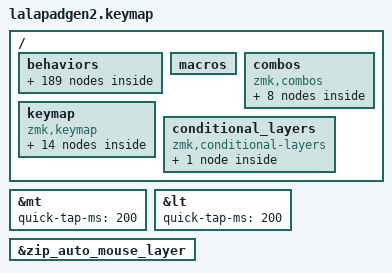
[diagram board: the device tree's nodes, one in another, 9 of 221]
#include <input/processors.dtsi>
#include <dt-bindings/zmk/zip_dynamic_scale.h>
#include <behaviors.dtsi>
#include <dt-bindings/zmk/bt.h>
#include <dt-bindings/zmk/keys.h>
#include <dt-bindings/zmk/outputs.h>
#include <dt-bindings/zmk/pointing.h>
#include <behaviors/kana.dtsi>
#include <dt-bindings/kana/kanji.h>
#include <behaviors/mouse_button_toggle.dtsi>
#include <dt-bindings/lalapad/cursor_slow.h>
#include <dt-bindings/lalapad/tp_keys.h>
#include <dt-bindings/lalapad/tp_positions.h>

#define DEFAULT_LAYER   0
#define CONTROL_LAYER   13
#define SECONDARY_LAYER 1
#define TERTIARY_LAYER  2
#define SYSTEM_LAYER    3
#define MOUSE_LAYER     4
#define KANA_LAYER      5
#define KANA_L_LAYER    6
#define KANA_R_LAYER    7
#define KANA_SYM_LAYER  8
#define LEFT_HAND_LAYER  9
#define LEFT_HAND2_LAYER 10
#define LEFT_HAND3_LAYER 11
#define LEFT_HAND4_LAYER 12

// &mt・&lt: 短く押してから 200ms 以内にもう一度押し続けると、長押しにせずタップを押し続ける（Space の連続入力など）。
// &mt は今どこにも置いていない（エディタで置いたときの既定）
&mt { quick-tap-ms = <200>; };

&lt { quick-tap-ms = <200>; };

// オートマウスレイヤー（lalapadgen2.dtsi）のうち、マウスレイヤーに結びつく設定
// - layer: トラックパッドを操作したときに有効にするレイヤー。timeout-ms: 指とキーを離してから解除するまでの時間
// - excluded-layers: 数字・記号レイヤーの間は、トラックパッドを操作してもマウスレイヤーにしない
// - excluded-positions: マウスレイヤーで &trans でも、押しても解除せず、押している間は時間切れにしない位置
//   （トラックパッドのクリック・ジェスチャー 52〜67。POS_TP_* は dt-bindings/lalapad/tp_positions.h。離してから数え直す）
// - passive-positions: マウスレイヤーに割り当てがあっても、押しても解除も延長もしない位置（親指の段の 30〜41 のうち、
//   33・34 以外。マウスレイヤーで &trans の位置（36〜38）は、ほかのキーと同じく押すと解除する）
&zip_auto_mouse_layer {
    layer = <MOUSE_LAYER>;
    timeout-ms = <350>;
    excluded-layers = <SECONDARY_LAYER TERTIARY_LAYER>;
    excluded-positions = <
        POS_TP_LCLK_L POS_TP_RCLK_L POS_TP_MCLK_L POS_TP_LCLK_R POS_TP_RCLK_R POS_TP_MCLK_R
        POS_TP_SWIPE_RIGHT_L POS_TP_SWIPE_LEFT_L POS_TP_SWIPE_UP_L POS_TP_SWIPE_DOWN_L POS_TP_PINCH_L
        POS_TP_SWIPE_RIGHT_R POS_TP_SWIPE_LEFT_R POS_TP_SWIPE_UP_R POS_TP_SWIPE_DOWN_R POS_TP_PINCH_R
    >;
    passive-positions = <30 31 32 35 36 37 38 39 40 41>;
};


/ {
    behaviors {
        zip_dyn_scale: zip_dyn_scale {
            compatible = "zmk,behavior-zip-dynamic-scale";
            #binding-cells = <2>;
        };

        zip_dyn_scale_set: zip_dyn_scale_set {
            compatible = "zmk,behavior-zip-dynamic-scale-set";
            #binding-cells = <2>;
        };

        // Num Word（自作モジュール lalapad/ の zmk,behavior-word-layer）: 数字レイヤーを、数字と continue-list のキー
        // （Backspace・Delete・. , + - * / =）を押している間だけ続け、ほかのキーを押すと自動で戻す。Shift などの修飾キーでは
        // 戻さない（ignore-modifiers）。ほかの操作（20＋21 のコンボの &to など）で数字レイヤーが解除されたら、こちらも終わる。
        // 記号レイヤー（38）を押したら終える（exit-layers）: 数字レイヤーと記号レイヤーが同時に有効になると
        // システムレイヤー（bootloader・BT_CLR など）になるため。Num Word の間に 38 を押すと、記号レイヤーになる。
        // 使い方: &num_word SECONDARY_LAYER
        num_word: num_word {
            compatible = "zmk,behavior-word-layer";
            #binding-cells = <1>;
            continue-list = <BACKSPACE DELETE DOT COMMA PLUS MINUS STAR FSLH EQUAL>;
            ignore-numbers;
            ignore-modifiers;
            exit-layers = <TERTIARY_LAYER>;
        };

        // 33 の長押し: 押している間だけ数字レイヤー（&mo と同じ）。Num Word の間に押したら、Num Word を引き継ぐ
        // （ほかのキーや 38 を押しても数字レイヤーのまま。33 と 38 でシステムレイヤーになる）。
        // 使い方: &num_hold SECONDARY_LAYER
        num_hold: num_hold {
            compatible = "zmk,behavior-word-layer";
            #binding-cells = <1>;
            momentary;
        };

        // 33: タップで Num Word（数字レイヤーを、数字を打っている間だけ続ける）、長押しで今までどおり押している間だけ
        // 数字レイヤー（num_hold）。長押しの間にほかのキーを押したら、すぐに長押しとして扱う（hold-preferred）。
        // 使い方: &num_mo SECONDARY_LAYER SECONDARY_LAYER
        num_mo: num_mo {
            compatible = "zmk,behavior-hold-tap";
            #binding-cells = <2>;
            flavor = "hold-preferred";
            tapping-term-ms = <200>;
            bindings = <&num_hold>, <&num_word>;
        };

        mt2: mod_tap2 {
            compatible = "zmk,behavior-hold-tap";
            #binding-cells = <2>;
            flavor = "tap-preferred";
            tapping-term-ms = <350>;
            quick-tap-ms = <200>;
            // require-prior-idle-ms（以前は 125）は外した。直前の打鍵から 125ms 以内に押すと、長押ししても
            // Shift にならず、押したままのタップとして rrrr と連続入力になったため。戻すときは次の行を足す
            //   require-prior-idle-ms = <125>;
            bindings = <&kp>, <&kp>;
        };

        // ===== カスタムキー（エディタで使いたいレイヤーに割り当てる） =====
        // 名前の頭で種類を分けている（clk_: クリック、cur_: カーソル、mod_: 修飾キー、swap_: ウィンドウの切り替え、scr_: スクロール、lyr_: レイヤー、num_: Num Word、link_: Chrome のリンク、tp_: トラックパッドでキー操作、ks_: かなと一緒に打つ記号、pair_: カッコ、sym_: 記号、kj_: 漢字 1 文字、kana_: かな）。
        // display-name は ZMK Studio の一覧とキーの上に出る名前（キーの上は 9 文字まで）。

        // --- clk_: クリック押しっぱなし（もう一度押す、または同じボタンのクリックで解除） ---
        // 左クリック押しっぱなし（旧 D.LCK）
        clk_lock_l: clk_lock_l {
            compatible = "zmk,behavior-mouse-button-toggle";
            display-name = "L Lock";
            #binding-cells = <0>;
            button = <LCLK>;
        };
        // 中クリック押しっぱなし（旧 D.MID）
        clk_lock_m: clk_lock_m {
            compatible = "zmk,behavior-mouse-button-toggle";
            display-name = "M Lock";
            #binding-cells = <0>;
            button = <MCLK>;
        };
        // 右クリック押しっぱなし（旧 D.RCK）
        clk_lock_r: clk_lock_r {
            compatible = "zmk,behavior-mouse-button-toggle";
            display-name = "R Lock";
            #binding-cells = <0>;
            button = <RCLK>;
        };

        // --- cur_: カーソル低速（1/3） ---
        // 押している間、カーソル低速（旧 SLOW）
        cur_slow_hold: cur_slow_hold {
            compatible = "zmk,behavior-cursor-slow";
            display-name = "Slow Hold";
            #binding-cells = <0>;
            mode = <CURSOR_SLOW_HOLD>;
        };
        // 押すたびにカーソル低速のオン・オフ（旧 T.SLO）
        cur_slow_toggle: cur_slow_toggle {
            compatible = "zmk,behavior-cursor-slow";
            display-name = "Slow Tog";
            #binding-cells = <0>;
            mode = <CURSOR_SLOW_TOGGLE>;
        };
        // 次のキーを押すまでカーソル低速（旧 O.SLO）
        cur_slow_once: cur_slow_once {
            compatible = "zmk,behavior-cursor-slow";
            display-name = "Slow Once";
            #binding-cells = <0>;
            mode = <CURSOR_SLOW_ONESHOT>;
        };

        // --- mod_: 修飾キー押しっぱなし（もう一度押すと解除） ---
        // Left Alt 押しっぱなし（旧 A.LCK）
        mod_lock_alt: mod_lock_alt {
            compatible = "zmk,behavior-key-lock";
            display-name = "Alt Lock";
            #binding-cells = <0>;
            keycode = <LALT>;
        };
        // Left Ctrl 押しっぱなし（旧 C.LCK）
        mod_lock_ctrl: mod_lock_ctrl {
            compatible = "zmk,behavior-key-lock";
            display-name = "Ctrl Lock";
            #binding-cells = <0>;
            keycode = <LCTRL>;
        };
        // Left Shift 押しっぱなし（旧 S.LCK）
        mod_lock_shift: mod_lock_shift {
            compatible = "zmk,behavior-key-lock";
            display-name = "Shft Lock";
            #binding-cells = <0>;
            keycode = <LSHIFT>;
        };
        // Left GUI（Win）押しっぱなし（旧 W.LCK）
        mod_lock_win: mod_lock_win {
            compatible = "zmk,behavior-key-lock";
            display-name = "Win Lock";
            #binding-cells = <0>;
            keycode = <LGUI>;
        };

        // --- swap_: ウィンドウの切り替え（Alt+Tab。自作モジュール lalapad/ の zmk,behavior-alt-tab） ---
        // 最初に押したときに Alt を押したままにして、押すたびに Tab（swap_prev は Shift+Tab）を送る。
        // 押し始めたときのレイヤーを離す（&mo のキーを離す）か、ほかのキー（キーコードを送るもの。クリックやレイヤーのキーは除く）を押すと
        // Alt を離して、選んだウィンドウに切り替わる。
        // swap_next と swap_prev は Alt を共有するので、どちらから押し始めても、途中で入れ替えてもよい
        swap_next: swap_next {
            compatible = "zmk,behavior-alt-tab";
            display-name = "Alt Tab";
            #binding-cells = <0>;
        };
        swap_prev: swap_prev {
            compatible = "zmk,behavior-alt-tab";
            display-name = "AltShTab";
            #binding-cells = <0>;
            reverse;
        };

        // --- scr_: スクロール ---
        // 押している間だけ、トラックパッドの2本指スクロールを縦か横のどちらかにそろえる（スクロールスナップ）。
        // レイヤーは使わない。実際の処理は lalapadgen2.dtsi の &zip_scroll_snap_gate_R / _L
        scr_snap_hold: scr_snap_hold {
            compatible = "zmk,behavior-scroll-snap-hold";
            display-name = "Snap Hold";
            #binding-cells = <0>;
        };

        // --- lyr_: レイヤー ---
        // レイヤーを固定する（Layer Lock。自作モジュール lalapad/ の zmk,behavior-layer-lock）。押すと、このキーを置いたレイヤーを
        // 固定する（&mo のキーを離しても、オートマウスレイヤーの時間切れでも切れない。マウスレイヤーでは、&trans のキーを
        // 押しても切れず、そのキーは下のレイヤーのキーとして入力される）。もう一度押すと固定をやめて、そのレイヤーを解除する
        // （オートマウスレイヤーなら、ふだんどおり手を離してから時間を数え直す）。Default と system_layer（数字＋記号で
        // 有効になるレイヤー）以外のどのレイヤーにも置ける。かなのレイヤーの固定は、かなモードを抜けるとやめる
        lyr_lock: lyr_lock {
            compatible = "zmk,behavior-layer-lock";
            display-name = "Lyr Lock";
            #binding-cells = <0>;
        };

        // --- link_: Chrome のリンク ---
        // カーソルを合わせたリンクを、シークレットウィンドウで開く。右クリックでメニューを出し、
        // メニューの「シークレット ウィンドウでリンクを開く」のアクセスキー G を押す（メニューが出るのを 200ms 待つ）
        link_incognito: link_incognito {
            compatible = "zmk,behavior-macro";
            #binding-cells = <0>;
            wait-ms = <0>;
            tap-ms = <30>;
            bindings
                = <&macro_wait_time 200>
                , <&mkp RCLK>
                , <&macro_wait_time 0>
                , <&kp G>
                ;
            display-name = "Incognito";
        };

        // --- tp_: トラックパッドをキー操作に変える（自作モジュール lalapad/ の zmk,behavior-tp-keys・zmk,behavior-tp-stroke） ---
        // 押している間だけ、トラックパッドの動きを、カーソル・スクロールの代わりにキーの入力に変える
        // （押している間のタップ・ジェスチャーは捨てる）。実際の処理は lalapadgen2.dtsi のリスナーに入れた &zip_tp_keys。
        // 直下の bindings はどのレイヤーでも使う既定。レイヤーごとに変えるときは、子ノード（表）に layers（使うレイヤー）と
        // bindings を書き足す（このキーを押したときに有効なレイヤーを上から見て、表のあるレイヤーの表を使う。表の &trans は
        // 下のレイヤーの表、最後に既定を見る）。左右のトラックパッドで変えるときは left-bindings・right-bindings に書く。
        // 例: num { layers = <SECONDARY_LAYER>; bindings = <...>; };
        // tp-keys の bindings は 8 つ: 1 本指を上・下・左・右へ動かしたとき、2 本指を上・下・左・右へ動かしたとき
        // （2 本指も指を動かした向き。スクロールの向きではない）。4 つとも &trans にした側は、変えずにカーソル（スクロール）のまま。
        // 動き始めの向きで縦か横かを決め、指が触れ直す・離れるか、このキーを押す・離すまで変えない。
        // *-step は 1 回送るのに必要な動きの量（トラックパッドの生の値。速度の設定には影響されない）。
        // 矢印: 1 本指で ←→↑↓、2 本指で上下が PgUp・PgDn、左右が Home・End
        tp_arrow: tp_arrow {
            compatible = "zmk,behavior-tp-keys";
            #binding-cells = <0>;
            bindings
                = <&kp UP>, <&kp DOWN>, <&kp LEFT>, <&kp RIGHT>
                , <&kp PAGE_UP>, <&kp PAGE_DOWN>, <&kp HOME>, <&kp END>
                ;
            cursor-step = <150>;
            scroll-step = <300>;
            display-name = "TP Arrow";
        };
        // ダイヤル: 1 本指で上下が音量、左右がタブ（Ctrl+Shift+Tab・Ctrl+Tab）。
        // 2 本指で上下がウィンドウの切り替え（指を上へ swap_prev・下へ swap_next。このキーを押したレイヤーが切れるか
        // （マウスレイヤーなら、キーとトラックパッドから手を離して 350ms 後）、ほかのキーを押すと、選んだウィンドウに
        // 切り替わる）、左右が仮想デスクトップ（Ctrl+Win+←・→）
        tp_dial: tp_dial {
            compatible = "zmk,behavior-tp-keys";
            #binding-cells = <0>;
            bindings
                = <&kp C_VOL_UP>, <&kp C_VOL_DN>, <&kp LC(LS(TAB))>, <&kp LC(TAB)>
                , <&swap_prev>, <&swap_next>, <&kp LC(LG(LEFT))>, <&kp LC(LG(RIGHT))>
                ;
            cursor-step = <300>;
            scroll-step = <300>;
            display-name = "TP Dial";
        };
        // 一筆書き: 押したまま 1 本指で線を描き、指（またはこのキー）を離すと、描いた向きの並びに合うものを送る。
        // strokes（向きの並び）は全レイヤー共通。bindings は strokes と同じ数・同じ順番（レイヤーごと・左右ごとの書き方は上の tp-keys と同じ）。
        // ← 戻る、→ 進む、↑ 新しいタブ、↓ 再読み込み、↓→ タブを閉じる、↓← 閉じたタブを開き直す、
        // ↑← 前のタブ、↑→ 次のタブ、→↓ シークレットウィンドウ
        tp_draw: tp_draw {
            compatible = "zmk,behavior-tp-stroke";
            #binding-cells = <0>;
            strokes = <
                TP_STROKE1(TP_LEFT)
                TP_STROKE1(TP_RIGHT)
                TP_STROKE1(TP_UP)
                TP_STROKE1(TP_DOWN)
                TP_STROKE2(TP_DOWN, TP_RIGHT)
                TP_STROKE2(TP_DOWN, TP_LEFT)
                TP_STROKE2(TP_UP, TP_LEFT)
                TP_STROKE2(TP_UP, TP_RIGHT)
                TP_STROKE2(TP_RIGHT, TP_DOWN)
                >;
            bindings
                = <&kp LA(LEFT)>
                , <&kp LA(RIGHT)>
                , <&kp LC(T)>
                , <&kp F5>
                , <&kp LC(W)>
                , <&kp LC(LS(T))>
                , <&kp LC(LS(TAB))>
                , <&kp LC(TAB)>
                , <&kp LC(LS(N))>
                ;
            stroke-step = <300>;
            display-name = "TP Draw";
        };

        // --- sym_: 記号（Windows の Alt コードで送るもの。IME の状態やローマ字テーブルに関係なく入る） ---
        // ふだんは下のほうにあるローマ字テーブル版（sym_hbar_ime など）を使う。こちらは、ローマ字テーブルに
        // 登録していない PC で使うための予備（どのレイヤーにも置いていない）。
        // commit-ime: 先に IME オフで確定前の文字を確定させ、送り終えたら IME オンに戻す
        // （付けないと、確定前の文字があるときに、続きが記号の前に入ってしまう）
        // ―― （ホリゾンタルバー2つ。ダッシュ）を入力。日本語 Windows（cp932）の Alt+33116（Shift_JIS 0x815C）を2回送る。
        // Num Lock がオフなら一時的にオンにして、送り終えたら元に戻す（CONFIG_ZMK_HID_INDICATORS）
        sym_hbar: sym_hbar {
            compatible = "zmk,behavior-alt-code";
            display-name = "―― Alt";
            #binding-cells = <0>;
            codes = <33116 33116>;
            commit-ime;
            // 送る操作（押す・離す）が多い（最大 32）ので、pair_cquote と同じく間隔を広げる
            tap-ms = <10>;
            wait-ms = <10>;
        };
        // ～ （全角チルダ U+FF5E）を入力。日本語 Windows（cp932）の Alt+33120（Shift_JIS 0x8160）で送る。
        sym_tilde: sym_tilde {
            compatible = "zmk,behavior-alt-code";
            display-name = "～ Alt";
            #binding-cells = <0>;
            codes = <33120>;
            commit-ime;
        };
        // “” を入力してカーソルを中に。Alt+33127 = “、Alt+33128 = ”（Shift_JIS 0x8167・0x8168）
        pair_cquote: pair_cquote {
            compatible = "zmk,behavior-alt-code";
            display-name = "“” Alt";
            #binding-cells = <0>;
            codes = <33127 33128>;
            cursor-left = <1>;
            commit-ime;
            // 送る操作（押す・離す）が多い（最大 34）ので、Bluetooth の送信待ちがあふれないよう間隔を広げる
            tap-ms = <10>;
            wait-ms = <10>;
        };

        // --- kj_: 漢字 1 文字（ミニ漢直。Windows の Alt コードで送る。ローマ字テーブルに関係なく、確定した文字で入る） ---
        // 押すと Num Word を終える（「3時」のように打ったら、元のレイヤーに戻る）。数字レイヤーの 20〜22 に置いている
        // （20＋21 は左手用レイヤーに入る同時押しでもあるので、日・人 は同時押しの判定の分だけ遅れて入り、ほぼ同時に押すと入らない）。
        // commit-ime: IME オンで打った確定前の数字（「3」）を先に確定させる（付けないと「時3」の順に入る）。
        // 送り終えると IME オンになる（IME オフのときに押した場合も）
        // 時（Shift_JIS 0x8E9E）
        kj_ji: kj_ji {
            compatible = "zmk,behavior-alt-code";
            display-name = "時";
            #binding-cells = <0>;
            codes = <36510>;
            commit-ime;
        };
        // 人（Shift_JIS 0x906C）
        kj_hito: kj_hito {
            compatible = "zmk,behavior-alt-code";
            display-name = "人";
            #binding-cells = <0>;
            codes = <36972>;
            commit-ime;
        };
        // 日（Shift_JIS 0x93FA）
        kj_hi: kj_hi {
            compatible = "zmk,behavior-alt-code";
            display-name = "日";
            #binding-cells = <0>;
            codes = <37882>;
            commit-ime;
        };

        // --- kj_: 漢字 1 文字の続き（漢字の表 docs/google-ime/kanji.tsv の残りの字。Alt コード版。まだどのレイヤーにも置いていない） ---
        // 上の 時・人・日 と同じ作り（commit-ime つき）。名前は、漢字の表の名前（KJ_AU など）を小文字にしたもの。
        // 字 だけは、表の名前（KJ_JI）を小文字にすると上の kj_ji（時）と重なるので、kj_ji2 にしている。
        // 日本語 Windows だけで使える（Shift_JIS の文字コードの 10 進数を、Alt を押したままテンキーで打つ）。
        // 会（Shift_JIS 0x89EF）
        kj_au: kj_au {
            compatible = "zmk,behavior-alt-code";
            display-name = "会";
            #binding-cells = <0>;
            codes = <35311>;
            commit-ime;
        };
        // 部（Shift_JIS 0x9594）
        kj_bu: kj_bu {
            compatible = "zmk,behavior-alt-code";
            display-name = "部";
            #binding-cells = <0>;
            codes = <38292>;
            commit-ime;
        };
        // 分（Shift_JIS 0x95AA）
        kj_bun: kj_bun {
            compatible = "zmk,behavior-alt-code";
            display-name = "分";
            #binding-cells = <0>;
            codes = <38314>;
            commit-ime;
        };
        // 出（Shift_JIS 0x8F6F）
        kj_deru: kj_deru {
            compatible = "zmk,behavior-alt-code";
            display-name = "出";
            #binding-cells = <0>;
            codes = <36719>;
            commit-ime;
        };
        // 入（Shift_JIS 0x93FC）
        kj_hairu: kj_hairu {
            compatible = "zmk,behavior-alt-code";
            display-name = "入";
            #binding-cells = <0>;
            codes = <37884>;
            commit-ime;
        };
        // 話（Shift_JIS 0x9862）
        kj_hanasu: kj_hanasu {
            compatible = "zmk,behavior-alt-code";
            display-name = "話";
            #binding-cells = <0>;
            codes = <39010>;
            commit-ime;
        };
        // 方（Shift_JIS 0x95FB）
        kj_hou: kj_hou {
            compatible = "zmk,behavior-alt-code";
            display-name = "方";
            #binding-cells = <0>;
            codes = <38395>;
            commit-ime;
        };
        // 意（Shift_JIS 0x88D3）
        kj_i: kj_i {
            compatible = "zmk,behavior-alt-code";
            display-name = "意";
            #binding-cells = <0>;
            codes = <35027>;
            commit-ime;
        };
        // 言（Shift_JIS 0x8CBE）
        kj_iu: kj_iu {
            compatible = "zmk,behavior-alt-code";
            display-name = "言";
            #binding-cells = <0>;
            codes = <36030>;
            commit-ime;
        };
        // 字（Shift_JIS 0x8E9A）
        kj_ji2: kj_ji2 {
            compatible = "zmk,behavior-alt-code";
            display-name = "字";
            #binding-cells = <0>;
            codes = <36506>;
            commit-ime;
        };
        // 書（Shift_JIS 0x8F91）
        kj_kaku: kj_kaku {
            compatible = "zmk,behavior-alt-code";
            display-name = "書";
            #binding-cells = <0>;
            codes = <36753>;
            commit-ime;
        };
        // 漢（Shift_JIS 0x8ABF）
        kj_kan: kj_kan {
            compatible = "zmk,behavior-alt-code";
            display-name = "漢";
            #binding-cells = <0>;
            codes = <35519>;
            commit-ime;
        };
        // 考（Shift_JIS 0x8D6C）
        kj_kangaeru: kj_kangaeru {
            compatible = "zmk,behavior-alt-code";
            display-name = "考";
            #binding-cells = <0>;
            codes = <36204>;
            commit-ime;
        };
        // 感（Shift_JIS 0x8AB4）
        kj_kanjiru: kj_kanjiru {
            compatible = "zmk,behavior-alt-code";
            display-name = "感";
            #binding-cells = <0>;
            codes = <35508>;
            commit-ime;
        };
        // 風（Shift_JIS 0x9597）
        kj_kaze: kj_kaze {
            compatible = "zmk,behavior-alt-code";
            display-name = "風";
            #binding-cells = <0>;
            codes = <38295>;
            commit-ime;
        };
        // 気（Shift_JIS 0x8B43）
        kj_ki: kj_ki {
            compatible = "zmk,behavior-alt-code";
            display-name = "気";
            #binding-cells = <0>;
            codes = <35651>;
            commit-ime;
        };
        // 来（Shift_JIS 0x9788）
        kj_kuru: kj_kuru {
            compatible = "zmk,behavior-alt-code";
            display-name = "来";
            #binding-cells = <0>;
            codes = <38792>;
            commit-ime;
        };
        // 見（Shift_JIS 0x8CA9）
        kj_miru: kj_miru {
            compatible = "zmk,behavior-alt-code";
            display-name = "見";
            #binding-cells = <0>;
            codes = <36009>;
            commit-ime;
        };
        // 自（Shift_JIS 0x8EA9）
        kj_mizukara: kj_mizukara {
            compatible = "zmk,behavior-alt-code";
            display-name = "自";
            #binding-cells = <0>;
            codes = <36521>;
            commit-ime;
        };
        // 覚（Shift_JIS 0x8A6F）
        kj_oboeru: kj_oboeru {
            compatible = "zmk,behavior-alt-code";
            display-name = "覚";
            #binding-cells = <0>;
            codes = <35439>;
            commit-ime;
        };
        // 思（Shift_JIS 0x8E76）
        kj_omou: kj_omou {
            compatible = "zmk,behavior-alt-code";
            display-name = "思";
            #binding-cells = <0>;
            codes = <36470>;
            commit-ime;
        };
        // 知（Shift_JIS 0x926D）
        kj_shiru: kj_shiru {
            compatible = "zmk,behavior-alt-code";
            display-name = "知";
            #binding-cells = <0>;
            codes = <37485>;
            commit-ime;
        };
        // 的（Shift_JIS 0x9349）
        kj_teki: kj_teki {
            compatible = "zmk,behavior-alt-code";
            display-name = "的";
            #binding-cells = <0>;
            codes = <37705>;
            commit-ime;
        };
        // 取（Shift_JIS 0x8EE6）
        kj_toru: kj_toru {
            compatible = "zmk,behavior-alt-code";
            display-name = "取";
            #binding-cells = <0>;
            codes = <36582>;
            commit-ime;
        };
        // 打（Shift_JIS 0x91C5）
        kj_utsu: kj_utsu {
            compatible = "zmk,behavior-alt-code";
            display-name = "打";
            #binding-cells = <0>;
            codes = <37317>;
            commit-ime;
        };
        // 良（Shift_JIS 0x97C7）
        kj_yoi: kj_yoi {
            compatible = "zmk,behavior-alt-code";
            display-name = "良";
            #binding-cells = <0>;
            codes = <38855>;
            commit-ime;
        };
        // 全（Shift_JIS 0x9153）
        kj_zen: kj_zen {
            compatible = "zmk,behavior-alt-code";
            display-name = "全";
            #binding-cells = <0>;
            codes = <37203>;
            commit-ime;
        };
        // 間（Shift_JIS 0x8AD4）
        kj_aida: kj_aida {
            compatible = "zmk,behavior-alt-code";
            display-name = "間";
            #binding-cells = <0>;
            codes = <35540>;
            commit-ime;
        };
        // 味（Shift_JIS 0x96A1）
        kj_aji: kj_aji {
            compatible = "zmk,behavior-alt-code";
            display-name = "味";
            #binding-cells = <0>;
            codes = <38561>;
            commit-ime;
        };
        // 赤（Shift_JIS 0x90D4）
        kj_aka: kj_aka {
            compatible = "zmk,behavior-alt-code";
            display-name = "赤";
            #binding-cells = <0>;
            codes = <37076>;
            commit-ime;
        };
        // 明（Shift_JIS 0x96BE）
        kj_akarui: kj_akarui {
            compatible = "zmk,behavior-alt-code";
            display-name = "明";
            #binding-cells = <0>;
            codes = <38590>;
            commit-ime;
        };
        // 青（Shift_JIS 0x90C2）
        kj_ao: kj_ao {
            compatible = "zmk,behavior-alt-code";
            display-name = "青";
            #binding-cells = <0>;
            codes = <37058>;
            commit-ime;
        };
        // 場（Shift_JIS 0x8FEA）
        kj_ba: kj_ba {
            compatible = "zmk,behavior-alt-code";
            display-name = "場";
            #binding-cells = <0>;
            codes = <36842>;
            commit-ime;
        };
        // 大（Shift_JIS 0x91E5）
        kj_dai: kj_dai {
            compatible = "zmk,behavior-alt-code";
            display-name = "大";
            #binding-cells = <0>;
            codes = <37349>;
            commit-ime;
        };
        // 描（Shift_JIS 0x9560）
        kj_egaku: kj_egaku {
            compatible = "zmk,behavior-alt-code";
            display-name = "描";
            #binding-cells = <0>;
            codes = <38240>;
            commit-ime;
        };
        // 深（Shift_JIS 0x905B）
        kj_fukai: kj_fukai {
            compatible = "zmk,behavior-alt-code";
            display-name = "深";
            #binding-cells = <0>;
            codes = <36955>;
            commit-ime;
        };
        // 銀（Shift_JIS 0x8BE2）
        kj_gin: kj_gin {
            compatible = "zmk,behavior-alt-code";
            display-name = "銀";
            #binding-cells = <0>;
            codes = <35810>;
            commit-ime;
        };
        // 合（Shift_JIS 0x8D87）
        kj_gou: kj_gou {
            compatible = "zmk,behavior-alt-code";
            display-name = "合";
            #binding-cells = <0>;
            codes = <36231>;
            commit-ime;
        };
        // 初（Shift_JIS 0x8F89）
        kj_hajime: kj_hajime {
            compatible = "zmk,behavior-alt-code";
            display-name = "初";
            #binding-cells = <0>;
            codes = <36745>;
            commit-ime;
        };
        // 始（Shift_JIS 0x8E6E）
        kj_hajimeru: kj_hajimeru {
            compatible = "zmk,behavior-alt-code";
            display-name = "始";
            #binding-cells = <0>;
            codes = <36462>;
            commit-ime;
        };
        // 計（Shift_JIS 0x8C76）
        kj_hakaru: kj_hakaru {
            compatible = "zmk,behavior-alt-code";
            display-name = "計";
            #binding-cells = <0>;
            codes = <35958>;
            commit-ime;
        };
        // 離（Shift_JIS 0x97A3）
        kj_hanareru: kj_hanareru {
            compatible = "zmk,behavior-alt-code";
            display-name = "離";
            #binding-cells = <0>;
            codes = <38819>;
            commit-ime;
        };
        // 発（Shift_JIS 0x94AD）
        kj_hatsu: kj_hatsu {
            compatible = "zmk,behavior-alt-code";
            display-name = "発";
            #binding-cells = <0>;
            codes = <38061>;
            commit-ime;
        };
        // 早（Shift_JIS 0x9181）
        kj_hayai: kj_hayai {
            compatible = "zmk,behavior-alt-code";
            display-name = "早";
            #binding-cells = <0>;
            codes = <37249>;
            commit-ime;
        };
        // 変（Shift_JIS 0x95CF）
        kj_hen: kj_hen {
            compatible = "zmk,behavior-alt-code";
            display-name = "変";
            #binding-cells = <0>;
            codes = <38351>;
            commit-ime;
        };
        // 本（Shift_JIS 0x967B）
        kj_hon: kj_hon {
            compatible = "zmk,behavior-alt-code";
            display-name = "本";
            #binding-cells = <0>;
            codes = <38523>;
            commit-ime;
        };
        // 行（Shift_JIS 0x8D73）
        kj_iku: kj_iku {
            compatible = "zmk,behavior-alt-code";
            display-name = "行";
            #binding-cells = <0>;
            codes = <36211>;
            commit-ime;
        };
        // 色（Shift_JIS 0x9046）
        kj_iro: kj_iro {
            compatible = "zmk,behavior-alt-code";
            display-name = "色";
            #binding-cells = <0>;
            codes = <36934>;
            commit-ime;
        };
        // 回（Shift_JIS 0x89F1）
        kj_kai: kj_kai {
            compatible = "zmk,behavior-alt-code";
            display-name = "回";
            #binding-cells = <0>;
            codes = <35313>;
            commit-ime;
        };
        // 体（Shift_JIS 0x91CC）
        kj_karada: kj_karada {
            compatible = "zmk,behavior-alt-code";
            display-name = "体";
            #binding-cells = <0>;
            codes = <37324>;
            commit-ime;
        };
        // 系（Shift_JIS 0x8C6E）
        kj_kei: kj_kei {
            compatible = "zmk,behavior-alt-code";
            display-name = "系";
            #binding-cells = <0>;
            codes = <35950>;
            commit-ime;
        };
        // 聞（Shift_JIS 0x95B7）
        kj_kiku: kj_kiku {
            compatible = "zmk,behavior-alt-code";
            display-name = "聞";
            #binding-cells = <0>;
            codes = <38327>;
            commit-ime;
        };
        // 決（Shift_JIS 0x8C88）
        kj_kimeru: kj_kimeru {
            compatible = "zmk,behavior-alt-code";
            display-name = "決";
            #binding-cells = <0>;
            codes = <35976>;
            commit-ime;
        };
        // 金（Shift_JIS 0x8BE0）
        kj_kin: kj_kin {
            compatible = "zmk,behavior-alt-code";
            display-name = "金";
            #binding-cells = <0>;
            codes = <35808>;
            commit-ime;
        };
        // 個（Shift_JIS 0x8CC2）
        kj_ko: kj_ko {
            compatible = "zmk,behavior-alt-code";
            display-name = "個";
            #binding-cells = <0>;
            codes = <36034>;
            commit-ime;
        };
        // 事（Shift_JIS 0x8E96）
        kj_koto: kj_koto {
            compatible = "zmk,behavior-alt-code";
            display-name = "事";
            #binding-cells = <0>;
            codes = <36502>;
            commit-ime;
        };
        // 効（Shift_JIS 0x8CF8）
        kj_kou: kj_kou {
            compatible = "zmk,behavior-alt-code";
            display-name = "効";
            #binding-cells = <0>;
            codes = <36088>;
            commit-ime;
        };
        // 暗（Shift_JIS 0x88C3）
        kj_kurai: kj_kurai {
            compatible = "zmk,behavior-alt-code";
            display-name = "暗";
            #binding-cells = <0>;
            codes = <35011>;
            commit-ime;
        };
        // 黒（Shift_JIS 0x8D95）
        kj_kuro: kj_kuro {
            compatible = "zmk,behavior-alt-code";
            display-name = "黒";
            #binding-cells = <0>;
            codes = <36245>;
            commit-ime;
        };
        // 面（Shift_JIS 0x96CA）
        kj_men: kj_men {
            compatible = "zmk,behavior-alt-code";
            display-name = "面";
            #binding-cells = <0>;
            codes = <38602>;
            commit-ime;
        };
        // 難（Shift_JIS 0x93EF）
        kj_nan: kj_nan {
            compatible = "zmk,behavior-alt-code";
            display-name = "難";
            #binding-cells = <0>;
            codes = <37871>;
            commit-ime;
        };
        // 何（Shift_JIS 0x89BD）
        kj_nani: kj_nani {
            compatible = "zmk,behavior-alt-code";
            display-name = "何";
            #binding-cells = <0>;
            codes = <35261>;
            commit-ime;
        };
        // 慣（Shift_JIS 0x8AB5）
        kj_nareru: kj_nareru {
            compatible = "zmk,behavior-alt-code";
            display-name = "慣";
            #binding-cells = <0>;
            codes = <35509>;
            commit-ime;
        };
        // 々（Shift_JIS 0x8158）
        kj_noma: kj_noma {
            compatible = "zmk,behavior-alt-code";
            display-name = "々";
            #binding-cells = <0>;
            codes = <33112>;
            commit-ime;
        };
        // 起（Shift_JIS 0x8B4E）
        kj_okiru: kj_okiru {
            compatible = "zmk,behavior-alt-code";
            display-name = "起";
            #binding-cells = <0>;
            codes = <35662>;
            commit-ime;
        };
        // 多（Shift_JIS 0x91BD）
        kj_ooi: kj_ooi {
            compatible = "zmk,behavior-alt-code";
            display-name = "多";
            #binding-cells = <0>;
            codes = <37309>;
            commit-ime;
        };
        // 定（Shift_JIS 0x92E8）
        kj_sadameru: kj_sadameru {
            compatible = "zmk,behavior-alt-code";
            display-name = "定";
            #binding-cells = <0>;
            codes = <37608>;
            commit-ime;
        };
        // 撮（Shift_JIS 0x8E42）
        kj_satsu: kj_satsu {
            compatible = "zmk,behavior-alt-code";
            display-name = "撮";
            #binding-cells = <0>;
            codes = <36418>;
            commit-ime;
        };
        // 線（Shift_JIS 0x90FC）
        kj_senbun: kj_senbun {
            compatible = "zmk,behavior-alt-code";
            display-name = "線";
            #binding-cells = <0>;
            codes = <37116>;
            commit-ime;
        };
        // 者（Shift_JIS 0x8ED2）
        kj_sha: kj_sha {
            compatible = "zmk,behavior-alt-code";
            display-name = "者";
            #binding-cells = <0>;
            codes = <36562>;
            commit-ime;
        };
        // 白（Shift_JIS 0x9492）
        kj_shiro: kj_shiro {
            compatible = "zmk,behavior-alt-code";
            display-name = "白";
            #binding-cells = <0>;
            codes = <38034>;
            commit-ime;
        };
        // 速（Shift_JIS 0x91AC）
        kj_soku: kj_soku {
            compatible = "zmk,behavior-alt-code";
            display-name = "速";
            #binding-cells = <0>;
            codes = <37292>;
            commit-ime;
        };
        // 対（Shift_JIS 0x91CE）
        kj_tai: kj_tai {
            compatible = "zmk,behavior-alt-code";
            display-name = "対";
            #binding-cells = <0>;
            codes = <37326>;
            commit-ime;
        };
        // 手（Shift_JIS 0x8EE8）
        kj_te: kj_te {
            compatible = "zmk,behavior-alt-code";
            display-name = "手";
            #binding-cells = <0>;
            codes = <36584>;
            commit-ime;
        };
        // 点（Shift_JIS 0x935F）
        kj_ten: kj_ten {
            compatible = "zmk,behavior-alt-code";
            display-name = "点";
            #binding-cells = <0>;
            codes = <37727>;
            commit-ime;
        };
        // 所（Shift_JIS 0x8F8A）
        kj_tokoro: kj_tokoro {
            compatible = "zmk,behavior-alt-code";
            display-name = "所";
            #binding-cells = <0>;
            codes = <36746>;
            commit-ime;
        };
        // 解（Shift_JIS 0x89F0）
        kj_toku: kj_toku {
            compatible = "zmk,behavior-alt-code";
            display-name = "解";
            #binding-cells = <0>;
            codes = <35312>;
            commit-ime;
        };
        // 使（Shift_JIS 0x8E67）
        kj_tsukau: kj_tsukau {
            compatible = "zmk,behavior-alt-code";
            display-name = "使";
            #binding-cells = <0>;
            codes = <36455>;
            commit-ime;
        };
        // 詰（Shift_JIS 0x8B6C）
        kj_tsumeru: kj_tsumeru {
            compatible = "zmk,behavior-alt-code";
            display-name = "詰";
            #binding-cells = <0>;
            codes = <35692>;
            commit-ime;
        };
        // 動（Shift_JIS 0x93AE）
        kj_ugoku: kj_ugoku {
            compatible = "zmk,behavior-alt-code";
            display-name = "動";
            #binding-cells = <0>;
            codes = <37806>;
            commit-ime;
        };
        // 運（Shift_JIS 0x895E）
        kj_un: kj_un {
            compatible = "zmk,behavior-alt-code";
            display-name = "運";
            #binding-cells = <0>;
            codes = <35166>;
            commit-ime;
        };
        // 笑（Shift_JIS 0x8FCE）
        kj_warau: kj_warau {
            compatible = "zmk,behavior-alt-code";
            display-name = "笑";
            #binding-cells = <0>;
            codes = <36814>;
            commit-ime;
        };
        // 悪（Shift_JIS 0x88AB）
        kj_warui: kj_warui {
            compatible = "zmk,behavior-alt-code";
            display-name = "悪";
            #binding-cells = <0>;
            codes = <34987>;
            commit-ime;
        };
        // 用（Shift_JIS 0x9770）
        kj_you: kj_you {
            compatible = "zmk,behavior-alt-code";
            display-name = "用";
            #binding-cells = <0>;
            codes = <38768>;
            commit-ime;
        };
        // 外（Shift_JIS 0x8A4F）
        kj_soto: kj_soto {
            compatible = "zmk,behavior-alt-code";
            display-name = "外";
            #binding-cells = <0>;
            codes = <35407>;
            commit-ime;
        };
        // 昇（Shift_JIS 0x8FB8）
        kj_noboru: kj_noboru {
            compatible = "zmk,behavior-alt-code";
            display-name = "昇";
            #binding-cells = <0>;
            codes = <36792>;
            commit-ime;
        };
        // 上（Shift_JIS 0x8FE3）
        kj_ue: kj_ue {
            compatible = "zmk,behavior-alt-code";
            display-name = "上";
            #binding-cells = <0>;
            codes = <36835>;
            commit-ime;
        };
        // 前（Shift_JIS 0x914F）
        kj_mae: kj_mae {
            compatible = "zmk,behavior-alt-code";
            display-name = "前";
            #binding-cells = <0>;
            codes = <37199>;
            commit-ime;
        };
        // 内（Shift_JIS 0x93E0）
        kj_uchi: kj_uchi {
            compatible = "zmk,behavior-alt-code";
            display-name = "内";
            #binding-cells = <0>;
            codes = <37856>;
            commit-ime;
        };
        // 数（Shift_JIS 0x9094）
        kj_kazu: kj_kazu {
            compatible = "zmk,behavior-alt-code";
            display-name = "数";
            #binding-cells = <0>;
            codes = <37012>;
            commit-ime;
        };
        // 年（Shift_JIS 0x944E）
        kj_nen: kj_nen {
            compatible = "zmk,behavior-alt-code";
            display-name = "年";
            #binding-cells = <0>;
            codes = <37966>;
            commit-ime;
        };
        // 終（Shift_JIS 0x8F49）
        kj_owaru: kj_owaru {
            compatible = "zmk,behavior-alt-code";
            display-name = "終";
            #binding-cells = <0>;
            codes = <36681>;
            commit-ime;
        };
        // 左（Shift_JIS 0x8DB6）
        kj_hidari: kj_hidari {
            compatible = "zmk,behavior-alt-code";
            display-name = "左";
            #binding-cells = <0>;
            codes = <36278>;
            commit-ime;
        };
        // 以（Shift_JIS 0x88C8）
        kj_motte: kj_motte {
            compatible = "zmk,behavior-alt-code";
            display-name = "以";
            #binding-cells = <0>;
            codes = <35016>;
            commit-ime;
        };
        // 右（Shift_JIS 0x8945）
        kj_migi: kj_migi {
            compatible = "zmk,behavior-alt-code";
            display-name = "右";
            #binding-cells = <0>;
            codes = <35141>;
            commit-ime;
        };
        // 今（Shift_JIS 0x8DA1）
        kj_ima: kj_ima {
            compatible = "zmk,behavior-alt-code";
            display-name = "今";
            #binding-cells = <0>;
            codes = <36257>;
            commit-ime;
        };
        // 歳（Shift_JIS 0x8DCE）
        kj_sai: kj_sai {
            compatible = "zmk,behavior-alt-code";
            display-name = "歳";
            #binding-cells = <0>;
            codes = <36302>;
            commit-ime;
        };
        // 月（Shift_JIS 0x8C8E）
        kj_tsuki: kj_tsuki {
            compatible = "zmk,behavior-alt-code";
            display-name = "月";
            #binding-cells = <0>;
            codes = <35982>;
            commit-ime;
        };
        // 次（Shift_JIS 0x8E9F）
        kj_tsugi: kj_tsugi {
            compatible = "zmk,behavior-alt-code";
            display-name = "次";
            #binding-cells = <0>;
            codes = <36511>;
            commit-ime;
        };
        // 降（Shift_JIS 0x8D7E）
        kj_oriru: kj_oriru {
            compatible = "zmk,behavior-alt-code";
            display-name = "降";
            #binding-cells = <0>;
            codes = <36222>;
            commit-ime;
        };
        // 下（Shift_JIS 0x89BA）
        kj_shita: kj_shita {
            compatible = "zmk,behavior-alt-code";
            display-name = "下";
            #binding-cells = <0>;
            codes = <35258>;
            commit-ime;
        };
        // 後（Shift_JIS 0x8CE3）
        kj_ato: kj_ato {
            compatible = "zmk,behavior-alt-code";
            display-name = "後";
            #binding-cells = <0>;
            codes = <36067>;
            commit-ime;
        };
        // 先（Shift_JIS 0x90E6）
        kj_saki: kj_saki {
            compatible = "zmk,behavior-alt-code";
            display-name = "先";
            #binding-cells = <0>;
            codes = <37094>;
            commit-ime;
        };
        // ０（Shift_JIS 0x824F）
        kj_num0: kj_num0 {
            compatible = "zmk,behavior-alt-code";
            display-name = "０";
            #binding-cells = <0>;
            codes = <33359>;
            commit-ime;
        };
        // １（Shift_JIS 0x8250）
        kj_num1: kj_num1 {
            compatible = "zmk,behavior-alt-code";
            display-name = "１";
            #binding-cells = <0>;
            codes = <33360>;
            commit-ime;
        };
        // ２（Shift_JIS 0x8251）
        kj_num2: kj_num2 {
            compatible = "zmk,behavior-alt-code";
            display-name = "２";
            #binding-cells = <0>;
            codes = <33361>;
            commit-ime;
        };
        // ３（Shift_JIS 0x8252）
        kj_num3: kj_num3 {
            compatible = "zmk,behavior-alt-code";
            display-name = "３";
            #binding-cells = <0>;
            codes = <33362>;
            commit-ime;
        };
        // ４（Shift_JIS 0x8253）
        kj_num4: kj_num4 {
            compatible = "zmk,behavior-alt-code";
            display-name = "４";
            #binding-cells = <0>;
            codes = <33363>;
            commit-ime;
        };
        // ５（Shift_JIS 0x8254）
        kj_num5: kj_num5 {
            compatible = "zmk,behavior-alt-code";
            display-name = "５";
            #binding-cells = <0>;
            codes = <33364>;
            commit-ime;
        };
        // ６（Shift_JIS 0x8255）
        kj_num6: kj_num6 {
            compatible = "zmk,behavior-alt-code";
            display-name = "６";
            #binding-cells = <0>;
            codes = <33365>;
            commit-ime;
        };
        // ７（Shift_JIS 0x8256）
        kj_num7: kj_num7 {
            compatible = "zmk,behavior-alt-code";
            display-name = "７";
            #binding-cells = <0>;
            codes = <33366>;
            commit-ime;
        };
        // ８（Shift_JIS 0x8257）
        kj_num8: kj_num8 {
            compatible = "zmk,behavior-alt-code";
            display-name = "８";
            #binding-cells = <0>;
            codes = <33367>;
            commit-ime;
        };
        // ９（Shift_JIS 0x8258）
        kj_num9: kj_num9 {
            compatible = "zmk,behavior-alt-code";
            display-name = "９";
            #binding-cells = <0>;
            codes = <33368>;
            commit-ime;
        };
        // 進（Shift_JIS 0x9069）
        kj_susumu: kj_susumu {
            compatible = "zmk,behavior-alt-code";
            display-name = "進";
            #binding-cells = <0>;
            codes = <36969>;
            commit-ime;
        };
        // 遠（Shift_JIS 0x8993）
        kj_tooi: kj_tooi {
            compatible = "zmk,behavior-alt-code";
            display-name = "遠";
            #binding-cells = <0>;
            codes = <35219>;
            commit-ime;
        };
        // 止（Shift_JIS 0x8E7E）
        kj_tomaru: kj_tomaru {
            compatible = "zmk,behavior-alt-code";
            display-name = "止";
            #binding-cells = <0>;
            codes = <36478>;
            commit-ime;
        };
        // 同（Shift_JIS 0x93AF）
        kj_onaji: kj_onaji {
            compatible = "zmk,behavior-alt-code";
            display-name = "同";
            #binding-cells = <0>;
            codes = <37807>;
            commit-ime;
        };
        // 高（Shift_JIS 0x8D82）
        kj_takai: kj_takai {
            compatible = "zmk,behavior-alt-code";
            display-name = "高";
            #binding-cells = <0>;
            codes = <36226>;
            commit-ime;
        };
        // 低（Shift_JIS 0x92E1）
        kj_hikui: kj_hikui {
            compatible = "zmk,behavior-alt-code";
            display-name = "低";
            #binding-cells = <0>;
            codes = <37601>;
            commit-ime;
        };
        // 停（Shift_JIS 0x92E2）
        kj_tei: kj_tei {
            compatible = "zmk,behavior-alt-code";
            display-name = "停";
            #binding-cells = <0>;
            codes = <37602>;
            commit-ime;
        };
        // 小（Shift_JIS 0x8FAC）
        kj_chiisai: kj_chiisai {
            compatible = "zmk,behavior-alt-code";
            display-name = "小";
            #binding-cells = <0>;
            codes = <36780>;
            commit-ime;
        };
        // 中（Shift_JIS 0x9286）
        kj_naka: kj_naka {
            compatible = "zmk,behavior-alt-code";
            display-name = "中";
            #binding-cells = <0>;
            codes = <37510>;
            commit-ime;
        };
        // 最（Shift_JIS 0x8DC5）
        kj_mottomo: kj_mottomo {
            compatible = "zmk,behavior-alt-code";
            display-name = "最";
            #binding-cells = <0>;
            codes = <36293>;
            commit-ime;
        };
        // 異（Shift_JIS 0x88D9）
        kj_kotonaru: kj_kotonaru {
            compatible = "zmk,behavior-alt-code";
            display-name = "異";
            #binding-cells = <0>;
            codes = <35033>;
            commit-ime;
        };
        // 退（Shift_JIS 0x91DE）
        kj_shirizoku: kj_shirizoku {
            compatible = "zmk,behavior-alt-code";
            display-name = "退";
            #binding-cells = <0>;
            codes = <37342>;
            commit-ime;
        };
        // 近（Shift_JIS 0x8BDF）
        kj_chikai: kj_chikai {
            compatible = "zmk,behavior-alt-code";
            display-name = "近";
            #binding-cells = <0>;
            codes = <35807>;
            commit-ime;
        };
        // 心（Shift_JIS 0x9053）
        kj_kokoro: kj_kokoro {
            compatible = "zmk,behavior-alt-code";
            display-name = "心";
            #binding-cells = <0>;
            codes = <36947>;
            commit-ime;
        };
        // 違（Shift_JIS 0x88E1）
        kj_chigau: kj_chigau {
            compatible = "zmk,behavior-alt-code";
            display-name = "違";
            #binding-cells = <0>;
            codes = <35041>;
            commit-ime;
        };
        // 〇（Shift_JIS 0x815A）
        kj_rei: kj_rei {
            compatible = "zmk,behavior-alt-code";
            display-name = "〇";
            #binding-cells = <0>;
            codes = <33114>;
            commit-ime;
        };
        // 一（Shift_JIS 0x88EA）
        kj_ichi: kj_ichi {
            compatible = "zmk,behavior-alt-code";
            display-name = "一";
            #binding-cells = <0>;
            codes = <35050>;
            commit-ime;
        };
        // 二（Shift_JIS 0x93F1）
        kj_ni: kj_ni {
            compatible = "zmk,behavior-alt-code";
            display-name = "二";
            #binding-cells = <0>;
            codes = <37873>;
            commit-ime;
        };
        // 三（Shift_JIS 0x8E4F）
        kj_san: kj_san {
            compatible = "zmk,behavior-alt-code";
            display-name = "三";
            #binding-cells = <0>;
            codes = <36431>;
            commit-ime;
        };
        // 四（Shift_JIS 0x8E6C）
        kj_yon: kj_yon {
            compatible = "zmk,behavior-alt-code";
            display-name = "四";
            #binding-cells = <0>;
            codes = <36460>;
            commit-ime;
        };
        // 五（Shift_JIS 0x8CDC）
        kj_go: kj_go {
            compatible = "zmk,behavior-alt-code";
            display-name = "五";
            #binding-cells = <0>;
            codes = <36060>;
            commit-ime;
        };
        // 六（Shift_JIS 0x985A）
        kj_roku: kj_roku {
            compatible = "zmk,behavior-alt-code";
            display-name = "六";
            #binding-cells = <0>;
            codes = <39002>;
            commit-ime;
        };
        // 七（Shift_JIS 0x8EB5）
        kj_nana: kj_nana {
            compatible = "zmk,behavior-alt-code";
            display-name = "七";
            #binding-cells = <0>;
            codes = <36533>;
            commit-ime;
        };
        // 八（Shift_JIS 0x94AA）
        kj_hachi: kj_hachi {
            compatible = "zmk,behavior-alt-code";
            display-name = "八";
            #binding-cells = <0>;
            codes = <38058>;
            commit-ime;
        };
        // 九（Shift_JIS 0x8BE3）
        kj_kyuu: kj_kyuu {
            compatible = "zmk,behavior-alt-code";
            display-name = "九";
            #binding-cells = <0>;
            codes = <35811>;
            commit-ime;
        };
        // 十（Shift_JIS 0x8F5C）
        kj_juu: kj_juu {
            compatible = "zmk,behavior-alt-code";
            display-name = "十";
            #binding-cells = <0>;
            codes = <36700>;
            commit-ime;
        };
        // 百（Shift_JIS 0x9553）
        kj_hyaku: kj_hyaku {
            compatible = "zmk,behavior-alt-code";
            display-name = "百";
            #binding-cells = <0>;
            codes = <38227>;
            commit-ime;
        };
        // 千（Shift_JIS 0x90E7）
        kj_sen: kj_sen {
            compatible = "zmk,behavior-alt-code";
            display-name = "千";
            #binding-cells = <0>;
            codes = <37095>;
            commit-ime;
        };
        // 万（Shift_JIS 0x969C）
        kj_man: kj_man {
            compatible = "zmk,behavior-alt-code";
            display-name = "万";
            #binding-cells = <0>;
            codes = <38556>;
            commit-ime;
        };
        // 億（Shift_JIS 0x89AD）
        kj_oku: kj_oku {
            compatible = "zmk,behavior-alt-code";
            display-name = "億";
            #binding-cells = <0>;
            codes = <35245>;
            commit-ime;
        };

        // --- かな入力（自作モジュール lalapad/）。Keymap Editor が認識できるよう、定義はこのファイルに置く ---
        // かな・編集用のキーを送る（&kana_key KN_A など。ID は lalapad/include/dt-bindings/kana/kana.h。
        // KN_ = かな、KE_ = スペース・エンター・バックスペース・Esc・Tab）。記号は、下の zmk,behavior-kana-seq のキーで送る
        kana_key: kana_key {
            compatible = "zmk,behavior-kana";
            #binding-cells = <1>;
            display-name = "Kana";
        };
        // 漢字を送る（&kanji_key KJ_… など。名前と番号は lalapad/include/dt-bindings/kana/kanji.h。
        // docs/google-ime/kanji.tsv から docs/tools/gen_kanji.py で作る）。番号の符号（「;」＋英字 2 文字）を
        // かなと同じ送信キューで送り、PC 側の Google 日本語入力のローマ字テーブルが漢字に変える。かなモードの間だけ働く。
        // kanji.tsv の「同時押し」に書いたかなのキーを同時に押しても漢字が出る（同時とみなす時間は chord-ms。既定 40 ms）
        kanji_key: kanji_key {
            compatible = "zmk,behavior-kanji";
            #binding-cells = <1>;
            display-name = "Kanji";
        };
        // かな配列モードのオン／オフ（&kana_sw KANA_SW_ON / KANA_SW_OFF）。layer はかな単打面。
        // sub-layers は、かなモードを抜けるときにいっしょに解除するレイヤー（親指を押したまま抜けても残らないように）
        kana_sw: kana_sw {
            compatible = "zmk,behavior-kana-mode";
            #binding-cells = <1>;
            display-name = "Kana Mode";
            layer = <KANA_LAYER>;
            sub-layers = <KANA_L_LAYER KANA_R_LAYER KANA_SYM_LAYER>;
        };

        // --- 記号・カッコ（自作モジュール lalapad/ の zmk,behavior-kana-seq。keys に書いた打鍵を順に送る） ---
        // かな（&kana_key）と同じ送信待ちの列に並ぶので、かなのレイヤーにも、ほかのレイヤーにも置ける。
        // かなモードを抜ける処理の最中に押したときは捨て、送信待ちがあふれたときは順番を守って打ち切る
        // （ZMK 標準のマクロには、この処理がない）。新しい記号は、ここに同じ形で書き足すだけでよい。
        // ime-on: かなモードでないとき、打鍵の前に毎回 IME オン（LANGUAGE_1）を送る（入力後も IME はオンのまま）。
        // かなモード中は、ime-on の有無に関係なく、しばらく打っていなかったとき（と、接続先の切り替えやトラックパッドの
        // クリック・ジェスチャーの後）だけ IME オンを先に送る。

        // --- ks_: かなと一緒に打つ記号 ---
        ks_touten: ks_touten {
            compatible = "zmk,behavior-kana-seq";
            display-name = "、";
            #binding-cells = <0>;
            keys = <COMMA>;
            ime-on;
        };
        ks_kuten: ks_kuten {
            compatible = "zmk,behavior-kana-seq";
            display-name = "。";
            #binding-cells = <0>;
            keys = <DOT>;
            ime-on;
        };
        ks_chouon: ks_chouon {
            compatible = "zmk,behavior-kana-seq";
            display-name = "ー";
            #binding-cells = <0>;
            keys = <MINUS>;
            ime-on;
        };
        ks_excl: ks_excl {
            compatible = "zmk,behavior-kana-seq";
            display-name = "！";
            #binding-cells = <0>;
            keys = <EXCLAMATION>;
            ime-on;
        };
        ks_ques: ks_ques {
            compatible = "zmk,behavior-kana-seq";
            display-name = "？";
            #binding-cells = <0>;
            keys = <QUESTION>;
            ime-on;
        };

        // --- pair_: カッコの自動補完（開き・閉じを入力して ← でカーソルを中に置く） ---
        // 「」を入力してカーソルを中に。[ ] を Google 日本語入力で「」にする
        pair_kagi: pair_kagi {
            compatible = "zmk,behavior-kana-seq";
            display-name = "「」";
            #binding-cells = <0>;
            keys = <LEFT_BRACKET RIGHT_BRACKET LEFT>;
            ime-on;
        };
        // 『』を入力してカーソルを中に。Google 日本語入力の z[ z] で『』にする
        pair_nijukagi: pair_nijukagi {
            compatible = "zmk,behavior-kana-seq";
            display-name = "『』";
            #binding-cells = <0>;
            keys = <Z LEFT_BRACKET Z RIGHT_BRACKET LEFT>;
            ime-on;
        };
        // “” を入力してカーソルを中に。ローマ字テーブルの z{ z} で “ ” にする。
        // PC 側でローマ字テーブルに「z{ → “」「z} → ”」の登録が必要（標準のテーブルにはない）
        pair_cquote_ime: pair_cquote_ime {
            compatible = "zmk,behavior-kana-seq";
            display-name = "“”";
            #binding-cells = <0>;
            keys = <Z LEFT_BRACE Z RIGHT_BRACE LEFT>;
            ime-on;
        };
        // () を入力してカーソルを中に（かなモード以外では IME を切り替えない。IME オンなら（）になる）
        pair_paren: pair_paren {
            compatible = "zmk,behavior-kana-seq";
            display-name = "()";
            #binding-cells = <0>;
            keys = <LPAR RPAR LEFT>;
        };
        // "" を入力してカーソルを中に。先に IME オフ（LANGUAGE_2）を送って半角の "" にする（IME はオフのまま）。
        // 表示名は全角の ＂＂（文字列の中の \" は Zephyr のビルド（dts.cmake）が通らない）
        pair_dquote: pair_dquote {
            compatible = "zmk,behavior-kana-seq";
            display-name = "＂＂";
            #binding-cells = <0>;
            keys = <LANGUAGE_2 DOUBLE_QUOTES DOUBLE_QUOTES LEFT>;
        };

        // --- sym_: 記号（Google 日本語入力のローマ字テーブル経由） ---
        // … を入力。Google 日本語入力の z. で … にする
        sym_ellipsis: sym_ellipsis {
            compatible = "zmk,behavior-kana-seq";
            display-name = "…";
            #binding-cells = <0>;
            keys = <Z PERIOD>;
            ime-on;
        };
        // ―― （ホリゾンタルバー2つ。ダッシュ）を入力。ローマ字テーブルの z= で ― にするのを2回送る。
        // PC 側でローマ字テーブルに「z= → ―」の登録が必要（標準のテーブルにはない）
        sym_hbar_ime: sym_hbar_ime {
            compatible = "zmk,behavior-kana-seq";
            display-name = "――";
            #binding-cells = <0>;
            keys = <Z EQUAL Z EQUAL>;
            ime-on;
        };
        // ～ を入力。ローマ字テーブルの z- で ～（全角チルダ）にする（標準のテーブルの z- は 〜（波ダッシュ）。
        // docs/google-ime/romantable.txt で ～ に変えている）
        sym_tilde_ime: sym_tilde_ime {
            compatible = "zmk,behavior-kana-seq";
            display-name = "～";
            #binding-cells = <0>;
            keys = <Z MINUS>;
            ime-on;
        };
    };

    // エディタ（LaLapad-Gen2-Editor）が作るマクロ用。
    macros {
    };

    combos {
        compatible = "zmk,combos";

        // Esc・Tab は、数字レイヤー（SECONDARY）では働かない（1・2、6・7 を続けて素早く打ったときに出ないように）
        COMBO_ESC {
            bindings = <&kp ESCAPE>;
            key-positions = <0 1>;
            layers = <DEFAULT_LAYER CONTROL_LAYER TERTIARY_LAYER SYSTEM_LAYER MOUSE_LAYER>;
        };
        COMBO_TAB {
            bindings = <&kp TAB>;
            key-positions = <10 11>;
            layers = <DEFAULT_LAYER CONTROL_LAYER TERTIARY_LAYER SYSTEM_LAYER MOUSE_LAYER>;
        };
        // かなの単打の面の Esc・Tab は、かなと同じ送信キューで送る（まだ送り終えていないかなを追い越さないように）
        COMBO_KANA_ESC {
            bindings = <&kana_key KE_ESC>;
            key-positions = <0 1>;
            layers = <KANA_LAYER>;
        };
        COMBO_KANA_TAB {
            bindings = <&kana_key KE_TAB>;
            key-positions = <10 11>;
            layers = <KANA_LAYER>;
        };
        // Default レイヤーだけ: 16＋17 で IME オン、12＋13 で IME オフ。打っている途中で起きないよう、30ms 以内に
        // 両方を押したときだけ（timeout-ms）、直前のキーから 150ms 以上あけて押したときだけ（require-prior-idle-ms）
        COMBO_IME_ON {
            timeout-ms = <30>;
            bindings = <&kp LANGUAGE_1>;
            key-positions = <16 17>;
            layers = <DEFAULT_LAYER>;
            require-prior-idle-ms = <150>;
        };
        COMBO_IME_OFF {
            timeout-ms = <30>;
            bindings = <&kp LANGUAGE_2>;
            key-positions = <12 13>;
            layers = <DEFAULT_LAYER>;
            require-prior-idle-ms = <150>;
        };
        // 左手用レイヤー（10）へ: 数字レイヤーの 20＋21 だけ。Default に戻るのは left_hand_4（left_hand で 33 を長押し）の
        // 20＋21 だけ（ほかの左手用レイヤーの 20＋21 では戻らない）
        COMBO_LEFT_HAND_IN {
            bindings = <&to LEFT_HAND_LAYER>;
            key-positions = <20 21>;
            layers = <SECONDARY_LAYER>;
        };
        COMBO_LEFT_HAND_OUT {
            bindings = <&to DEFAULT_LAYER>;
            key-positions = <20 21>;
            layers = <LEFT_HAND4_LAYER>;
        };
    };

    keymap {
        compatible = "zmk,keymap";

        // layer_id_<番号>: は、レイヤーの見分けの番号（1〜255。ほかのレイヤーと重ねない）。レイヤーを作ったときに決め、
        // 名前を変えても並べ替えても変えない（レイヤーと一緒に動かす）。全部のレイヤーに付ける（一部だけだとビルドが止まる）。ファームウェアはこの番号で、ZMK Studio で保存した変更を、
        // レイヤーを並べ替え・足し・消しした後も同じレイヤーに付け替える（lalapad/src/layer_ids.c。README の「レイヤーの見分けの番号」）

        layer_id_1: DEFAULT_LAYER {
            display-name = "Default";
            bindings = <
            &kp F  &kp D  &kp L  &kp W  &kp J  &kp SEMI  &kp P  &kp O  &kp U  &kp COMMA
            &kp S  &kp T  &kp H  &kp C  &kp Y  &kp Q  &kp N  &kp A  &kp E  &kp I
            &mt2 LEFT_SHIFT X  &kp K  &kp M  &kp G  &kp V  &kp Z  &kp B  &kp SQT  &kp SLASH  &kp PERIOD
            &none  &none  &kp LEFT_ALT  &num_mo SECONDARY_LAYER SECONDARY_LAYER  &mt2 LEFT_SHIFT R  &kp ENTER  &kp BACKSPACE  &mt2 RIGHT_CONTROL SPACE  &mo TERTIARY_LAYER  &kp LWIN  &none  &none
            &tog CONTROL_LAYER  &kp RIGHT  &kp DOWN  &kp LEFT  &kp UP  &kp UP  &kp LEFT  &kp DOWN  &kp RIGHT  &kana_sw KANA_SW_ON
            &mkp LCLK  &mkp RCLK  &mkp MCLK  &mkp LCLK  &mkp RCLK  &mkp MCLK
            &mkp MB4  &mkp MB5  &kp LG(TAB)  &kp LG(D)  &kp LEFT_CONTROL  &mkp MB4  &mkp MB5  &kp LG(TAB)  &kp LG(D)  &kp LEFT_CONTROL
            >;
        };

        layer_id_3: SECONDARY_LAYER {
            display-name = "secondary_layer";
            bindings = <
            &kp NUMBER_1  &kp NUMBER_2  &kp NUMBER_3  &kp NUMBER_4  &kp NUMBER_5  &none  &kp DELETE  &sym_tilde_ime  &kp HASH  &none
            &kp NUMBER_6  &kp NUMBER_7  &kp NUMBER_8  &kp NUMBER_9  &kp NUMBER_0  &kp DLLR  &sym_ellipsis  &pair_kagi  &pair_nijukagi  &pair_paren
            &kj_hi  &kj_hito  &kj_ji  &kp COLON  &none  &none  &kp BACKSLASH  &kp ASTRK  &kp GRAVE  &kp EQUAL
            &trans  &trans  &trans  &trans  &kp LEFT_SHIFT  &trans  &trans  &trans  &trans  &trans  &trans  &kp KP_NUMLOCK
            &trans  &trans  &trans  &trans  &trans  &trans  &trans  &trans  &trans  &trans
            &trans  &trans  &trans  &trans  &trans  &trans
            &kp LC(LG(LEFT))  &kp LC(LG(RIGHT))  &trans  &trans  &trans  &kp LC(LG(LEFT))  &kp LC(LG(RIGHT))  &trans  &trans  &trans
            >;
        };

        layer_id_4: TERTIARY_LAYER {
            display-name = "tertiary_layer";
            bindings = <
            &none  &kp AMPS  &pair_cquote_ime  &swap_prev  &swap_next  &kp PAGE_UP  &kp HOME  &kp UP  &kp END  &kp PRINTSCREEN
            &kp AT  &kp EXCL  &kp MINUS  &sym_hbar_ime  &none  &kp PAGE_DOWN  &kp LEFT  &kp DOWN  &kp RIGHT  &none
            &kp BACKSLASH  &kp PRCNT  &kp CARET  &tp_arrow  &none  &none  &none  &none  &none  &none
            &trans  &trans  &trans  &trans  &kp LEFT_SHIFT  &kp LS(ENTER)  &trans  &trans  &trans  &trans  &trans  &kp CAPS
            &trans  &trans  &trans  &trans  &trans  &trans  &trans  &trans  &trans  &trans
            &trans  &trans  &trans  &trans  &trans  &trans
            &kp LG(RIGHT)  &kp LG(LEFT)  &trans  &trans  &trans  &kp LG(RIGHT)  &kp LG(LEFT)  &trans  &trans  &trans
            >;
        };

        layer_id_5: SYSTEM_LAYER {
            display-name = "system_layer";
            bindings = <
            &kp F1  &kp F2  &kp F3  &kp F4  &kp F5  &out OUT_TOG  &bt BT_SEL 0  &bt BT_SEL 1  &bt BT_SEL 2  &bt BT_SEL 3
            &kp F6  &kp F7  &kp F8  &kp F9  &kp F10  &sys_reset  &bootloader  &bt BT_CLR  &bt BT_CLR_ALL  &none
            &kp F11  &kp F12  &kp F13  &kp F14  &kp F15  &zip_dyn_scale ZDS_XY ZDS_INC  &zip_dyn_scale ZDS_XY ZDS_DEC  &zip_dyn_scale ZDS_SC ZDS_INC  &zip_dyn_scale ZDS_SC ZDS_DEC  &zip_dyn_scale ZDS_ALL ZDS_RST
            &trans  &trans  &trans  &trans  &trans  &trans  &trans  &trans  &trans  &trans  &trans  &trans
            &trans  &trans  &trans  &trans  &trans  &trans  &trans  &trans  &trans  &trans
            &trans  &trans  &trans  &trans  &trans  &trans
            &trans  &trans  &trans  &trans  &trans  &trans  &trans  &trans  &trans  &trans
            >;
        };

        layer_id_6: MOUSE_LAYER {
            display-name = "mouse_layer";
            bindings = <
            &tp_arrow  &kp LC(W)  &kp LC(LS(T))  &kp LC(A)  &none  &kp LC(LS(TAB))  &kp LC(TAB)  &none  &none  &lyr_lock
            &none  &mkp MCLK  &mkp RCLK  &mkp LCLK  &clk_lock_l  &kp RIGHT_CONTROL  &kp RIGHT_SHIFT  &link_incognito  &tp_draw  &tp_dial
            &kp LC(Z)  &kp LC(X)  &kp LC(C)  &kp LC(V)  &none  &none  &none  &kp RIGHT_ALT  &none  &none
            &none  &none  &trans  &trans  &scr_snap_hold  &trans  &trans  &trans  &trans  &trans  &none  &none
            &trans  &kp RS(RIGHT)  &trans  &kp LS(LEFT)  &kp LC(LS(C))  &trans  &trans  &trans  &trans  &trans
            &trans  &trans  &trans  &trans  &trans  &trans
            &trans  &trans  &trans  &trans  &trans  &trans  &trans  &trans  &trans  &trans
            >;
        };

        layer_id_7: KANA_LAYER {
            display-name = "kana";
            bindings = <
            &kana_key KN_A  &kana_key KN_I  &kana_key KN_U  &kana_key KN_E  &kana_key KN_O  &kana_key KN_KA  &kana_key KN_KI  &kana_key KN_KU  &kana_key KN_KE  &kana_key KN_KO
            &kana_key KN_SA  &kana_key KN_SI  &kana_key KN_SU  &kana_key KN_SE  &kana_key KN_SO  &kana_key KN_TA  &kana_key KN_TI  &kana_key KN_TU  &kana_key KN_TE  &kana_key KN_TO
            &kana_key KN_NA  &kana_key KN_NI  &kana_key KN_NU  &kana_key KN_NE  &kana_key KN_NO  &kana_key KN_HA  &kana_key KN_HI  &kana_key KN_HU  &kana_key KN_HE  &kana_key KN_HO
            &none  &none  &none  &kana_key KE_SPACE  &mo KANA_L_LAYER  &kana_key KE_ENTER  &kana_key KE_BSPC  &mo KANA_R_LAYER  &mo KANA_SYM_LAYER  &none  &none  &none
            &none  &trans  &trans  &trans  &trans  &trans  &trans  &trans  &trans  &kana_sw KANA_SW_OFF
            &trans  &trans  &trans  &trans  &trans  &trans
            &trans  &trans  &trans  &trans  &trans  &trans  &trans  &trans  &trans  &trans
            >;
        };

        layer_id_8: KANA_L_LAYER {
            display-name = "kana_left";
            bindings = <
            &kana_key KN_MA  &kana_key KN_MI  &kana_key KN_MU  &kana_key KN_ME  &kana_key KN_MO  &kana_key KN_YA  &kana_key KN_YU  &kana_key KN_YO  &kana_key KN_WA  &kana_key KN_WO
            &kana_key KN_RA  &kana_key KN_RI  &kana_key KN_RU  &kana_key KN_RE  &kana_key KN_RO  &kana_key KN_NN  &kana_key KN_GA  &kana_key KN_GI  &kana_key KN_GU  &kana_key KN_GE
            &kana_key KN_GO  &kana_key KN_ZA  &kana_key KN_ZI  &kana_key KN_ZU  &kana_key KN_ZE  &kana_key KN_ZO  &kana_key KN_DA  &kana_key KN_DI  &kana_key KN_DU  &kana_key KN_DE
            &trans  &trans  &trans  &trans  &trans  &trans  &trans  &trans  &trans  &trans  &trans  &trans
            &trans  &trans  &trans  &trans  &trans  &trans  &trans  &trans  &trans  &trans
            &trans  &trans  &trans  &trans  &trans  &trans
            &trans  &trans  &trans  &trans  &trans  &trans  &trans  &trans  &trans  &trans
            >;
        };

        layer_id_9: KANA_R_LAYER {
            display-name = "kana_right";
            bindings = <
            &kana_key KN_DO  &kana_key KN_BA  &kana_key KN_BI  &kana_key KN_BU  &kana_key KN_BE  &kana_key KN_BO  &kana_key KN_PA  &kana_key KN_PI  &kana_key KN_PU  &kana_key KN_PE
            &kana_key KN_PO  &kana_key KN_XYA  &kana_key KN_XYU  &kana_key KN_XYO  &kana_key KN_XA  &kana_key KN_XI  &kana_key KN_XU  &kana_key KN_XE  &kana_key KN_XO  &kana_key KN_XTU
            &kana_key KN_VU  &ks_touten  &ks_kuten  &ks_chouon  &sym_ellipsis  &ks_excl  &ks_ques  &pair_kagi  &sym_hbar_ime  &pair_paren
            &trans  &trans  &trans  &trans  &trans  &trans  &trans  &trans  &trans  &trans  &trans  &trans
            &trans  &trans  &trans  &trans  &trans  &trans  &trans  &trans  &trans  &trans
            &trans  &trans  &trans  &trans  &trans  &trans
            &trans  &trans  &trans  &trans  &trans  &trans  &trans  &trans  &trans  &trans
            >;
        };

        // かな記号面（かな単打面の位置38を押している間）。記号は後で配置する。今は文字キー（0〜29）を空にしている
        layer_id_10: KANA_SYM_LAYER {
            display-name = "kana_symbol";
            bindings = <
            &none  &none  &none  &none  &none  &none  &none  &none  &none  &none
            &none  &none  &none  &none  &none  &none  &none  &none  &none  &none
            &none  &none  &none  &none  &none  &none  &none  &none  &none  &none
            &trans  &trans  &trans  &trans  &trans  &trans  &trans  &trans  &trans  &trans  &trans  &trans
            &trans  &trans  &trans  &trans  &trans  &trans  &trans  &trans  &trans  &trans
            &trans  &trans  &trans  &trans  &trans  &trans
            &trans  &trans  &trans  &trans  &trans  &trans  &trans  &trans  &trans  &trans
            >;
        };

        layer_id_11: LEFT_HAND_LAYER {
            display-name = "left_hand";
            bindings = <
            &kp Q  &kp W  &kp E  &kp R  &kp T  &none  &none  &none  &none  &none
            &kp A  &kp S  &kp D  &kp F  &kp G  &none  &none  &none  &none  &none
            &kp Z  &kp X  &kp C  &kp V  &kp B  &none  &none  &none  &none  &none
            &kp LWIN  &kp LANGUAGE_2  &kp LANGUAGE_1  &lt LEFT_HAND4_LAYER SPACE  &mo LEFT_HAND2_LAYER  &mo LEFT_HAND3_LAYER  &none  &none  &none  &none  &none  &none
            &none  &trans  &trans  &trans  &trans  &none  &none  &none  &none  &none
            &trans  &trans  &trans  &trans  &trans  &trans
            &trans  &trans  &trans  &trans  &trans  &trans  &trans  &trans  &trans  &trans
            >;
        };

        layer_id_12: LEFT_HAND2_LAYER {
            display-name = "left_hand_2";
            bindings = <
            &kp Y  &kp U  &kp I  &kp O  &kp P  &none  &none  &none  &none  &none
            &kp H  &kp J  &kp K  &kp L  &kp MINUS  &none  &none  &none  &none  &none
            &kp N  &kp M  &kp COMMA  &kp PERIOD  &kp QMARK  &none  &none  &none  &none  &none
            &none  &none  &none  &none  &none  &none  &none  &none  &none  &none  &none  &none
            &none  &none  &none  &none  &none  &none  &none  &none  &none  &none
            &trans  &trans  &trans  &trans  &trans  &trans
            &trans  &trans  &trans  &trans  &trans  &trans  &trans  &trans  &trans  &trans
            >;
        };

        layer_id_13: LEFT_HAND3_LAYER {
            display-name = "left_hand_3";
            bindings = <
            &kp NUMBER_1  &kp NUMBER_2  &kp NUMBER_3  &kp NUMBER_4  &kp NUMBER_5  &none  &none  &none  &none  &none
            &kp NUMBER_6  &kp NUMBER_7  &kp NUMBER_8  &kp NUMBER_9  &kp NUMBER_0  &none  &none  &none  &none  &none
            &sym_hbar_ime  &sk LCTRL  &mod_lock_shift  &pair_cquote_ime  &pair_kagi  &none  &none  &none  &none  &none
            &none  &none  &none  &none  &none  &none  &none  &none  &none  &none  &none  &none
            &none  &none  &none  &none  &none  &none  &none  &none  &none  &none
            &trans  &trans  &trans  &trans  &trans  &trans
            &trans  &trans  &trans  &trans  &trans  &trans  &trans  &trans  &trans  &trans
            >;
        };

        layer_id_14: LEFT_HAND4_LAYER {
            display-name = "left_hand_4";
            bindings = <
            &kp ESCAPE  &kp HOME  &kp UP  &kp END  &kp PAGE_UP  &none  &none  &none  &none  &none
            &kp TAB  &kp LEFT  &kp DOWN  &kp RIGHT  &kp PAGE_DOWN  &none  &none  &none  &none  &none
            &none  &none  &link_incognito  &kp PAUSE_BREAK  &none  &none  &none  &none  &none  &none
            &none  &none  &none  &none  &none  &none  &none  &none  &none  &none  &none  &none
            &none  &none  &none  &none  &none  &none  &none  &none  &none  &none
            &trans  &trans  &trans  &trans  &trans  &trans
            &trans  &trans  &trans  &trans  &trans  &trans  &trans  &trans  &trans  &trans
            >;
        };

        // Control レイヤー（Default の 42 を押すたびに入る／戻る）。左右に、矢印・Page Up／Down・数字・F11 を置く（上の段は左右対称、矢印の段は左右とも同じ並び）。
        // Default のすぐ上に置くので、数字・記号・マウス・かなのレイヤーは、この上に重なって今までどおり使える。
        layer_id_2: CONTROL_LAYER {
            display-name = "Control";
            bindings = <
            &kp F11  &kp NUMBER_6  &kp UP  &kp NUMBER_9  &kp PAGE_UP  &kp PAGE_UP  &kp NUMBER_9  &kp UP  &kp NUMBER_6  &kp F11
            &none  &kp LEFT  &kp DOWN  &kp RIGHT  &kp PAGE_DOWN  &kp PAGE_DOWN  &kp LEFT  &kp DOWN  &kp RIGHT  &none
            &none  &none  &none  &none  &none  &none  &none  &none  &none  &none
            &trans  &trans  &trans  &trans  &trans  &trans  &trans  &trans  &trans  &trans  &trans  &trans
            &tog CONTROL_LAYER  &trans  &trans  &trans  &trans  &trans  &trans  &trans  &trans  &trans
            &trans  &trans  &trans  &trans  &trans  &trans
            &trans  &trans  &trans  &trans  &trans  &trans  &trans  &trans  &trans  &trans
            >;
        };
    };

    conditional_layers {
        compatible = "zmk,conditional-layers";

        Cond_Syslayer {
            if-layers = <SECONDARY_LAYER TERTIARY_LAYER>;
            then-layer = <SYSTEM_LAYER>;
        };
    };
};
